# STM32F102 register map
File version: 1.2
CPU: CM3 r1p1, little endian, no MPU, no FPU, 4 interrupt priority bits
Registers are 32-bit, read-write, reset 0x0 unless marked. A register's access mark holds for its fields unless they carry their own. Offsets are from the block's base; [hi:lo] are bit positions; {n}, {i} and the like mark numbered series; 'fields as' and 'values as' point back to an identical list.

## CRC — CRC calculation unit
Base 0x40023000
0x00 DR reset 0xFFFFFFFF — Data register
  [31:0] DR — Data Register
0x04 IDR — Independent Data register
  [7:0] IDR
0x08 CR wo — Control register
  [0] RESET — Reset bit

## FLASH
Base 0x40022000
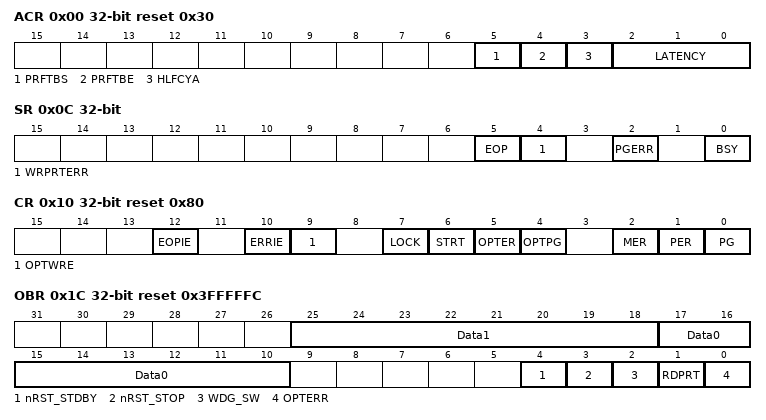
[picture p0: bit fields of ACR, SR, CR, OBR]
0x00 ACR access per field reset 0x30 — Flash access control register
  [5] PRFTBS ro — Prefetch buffer status
  [4] PRFTBE rw — Prefetch buffer enable
  [3] HLFCYA rw — Flash half cycle access enable
  [2:0] LATENCY rw
0x04 KEYR wo — Flash key register
  [31:0] KEY — FPEC key
0x08 OPTKEYR wo — Flash option key register
  [31:0] OPTKEY — Option byte key
0x0C SR access per field — Status register
  [5] EOP rw — End of operation
  [4] WRPRTERR rw — Write protection error
  [2] PGERR rw — Programming error
  [0] BSY ro — Busy
0x10 CR reset 0x80 — Control register
  [12] EOPIE — End of operation interrupt enable
  [10] ERRIE — Error interrupt enable
  [9] OPTWRE — Option bytes write enable
  [7] LOCK
  [6] STRT — Start
  [5] OPTER — Option byte erase
  [4] OPTPG — Option byte programming
  [2] MER — Mass Erase
  [1] PER — Page Erase
  [0] PG — Programming
0x14 AR wo — Flash address register
  [31:0] FAR — Flash Address
0x1C OBR ro reset 0x3FFFFFC — Option byte register
  [25:18] Data1
  [17:10] Data0
  [4] nRST_STDBY
  [3] nRST_STOP
  [2] WDG_SW
  [1] RDPRT — Read protection
  [0] OPTERR — Option byte error
0x20 WRPR ro reset 0xFFFFFFFF — Write protection register
  [31:0] WRP — Write protect

## DBG — Debug support
Base 0xE0042000
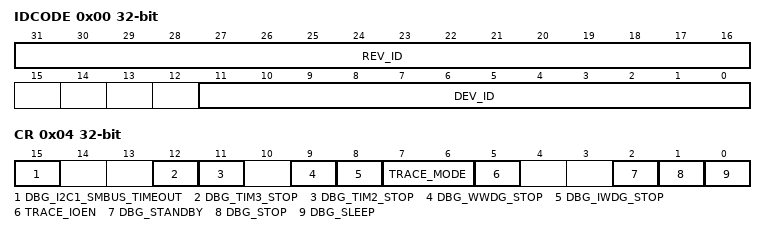
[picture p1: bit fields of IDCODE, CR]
0x00 IDCODE ro — DBGMCU_IDCODE
  [31:16] REV_ID, [11:0] DEV_ID
0x04 CR — DBGMCU_CR
  [15] DBG_I2C1_SMBUS_TIMEOUT, [12] DBG_TIM3_STOP, [11] DBG_TIM2_STOP, [9] DBG_WWDG_STOP, [8] DBG_IWDG_STOP, [7:6] TRACE_MODE, [5] TRACE_IOEN, [2] DBG_STANDBY, [1] DBG_STOP, [0] DBG_SLEEP

## BKP — Backup registers
Base 0x40006C00
0x00 DR1 — Backup data register (BKP_DR)
  [15:0] D1 — Backup data
0x04 DR2 — Backup data register (BKP_DR)
  [15:0] D2 — Backup data
0x08 DR3 — Backup data register (BKP_DR)
  [15:0] D3 — Backup data
0x0C DR4 — Backup data register (BKP_DR)
  [15:0] D4 — Backup data
0x10 DR5 — Backup data register (BKP_DR)
  [15:0] D5 — Backup data
0x14 DR6 — Backup data register (BKP_DR)
  [15:0] D6 — Backup data
0x18 DR7 — Backup data register (BKP_DR)
  [15:0] D7 — Backup data
0x1C DR8 — Backup data register (BKP_DR)
  [15:0] D8 — Backup data
0x20 DR9 — Backup data register (BKP_DR)
  [15:0] D9 — Backup data
0x24 DR10 — Backup data register (BKP_DR)
  [15:0] D10 — Backup data
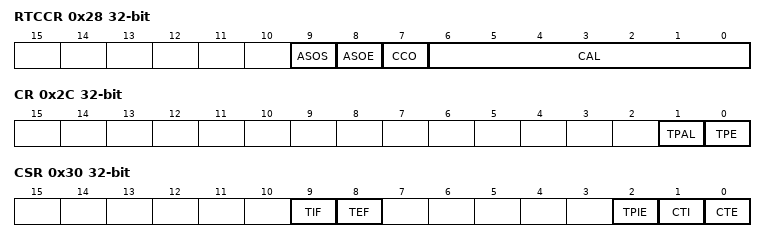
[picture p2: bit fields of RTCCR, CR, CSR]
0x28 RTCCR — RTC clock calibration register (BKP_RTCCR)
  [9] ASOS — Alarm or second output selection
  [8] ASOE — Alarm or second output enable
  [7] CCO — Calibration Clock Output
  [6:0] CAL — Calibration value
0x2C CR — Backup control register (BKP_CR)
  [1] TPAL — Tamper pin active level
  [0] TPE — Tamper pin enable
0x30 CSR access per field — BKP_CSR control/status register (BKP_CSR)
  [9] TIF ro — Tamper Interrupt Flag
  [8] TEF ro — Tamper Event Flag
  [2] TPIE rw — Tamper Pin interrupt enable
  [1] CTI wo — Clear Tamper Interrupt
  [0] CTE wo — Clear Tamper event
{0x10+4i} DR{i} (i=11..13) — Backup data register (BKP_DR)
  [15:0] DR{i} — Backup data
{0x10+4i} DR{i} (i=14..42) — Backup data register (BKP_DR)
  [15:0] D{i} — Backup data

## FSMC — Flexible static memory controller
Base 0xA0000000
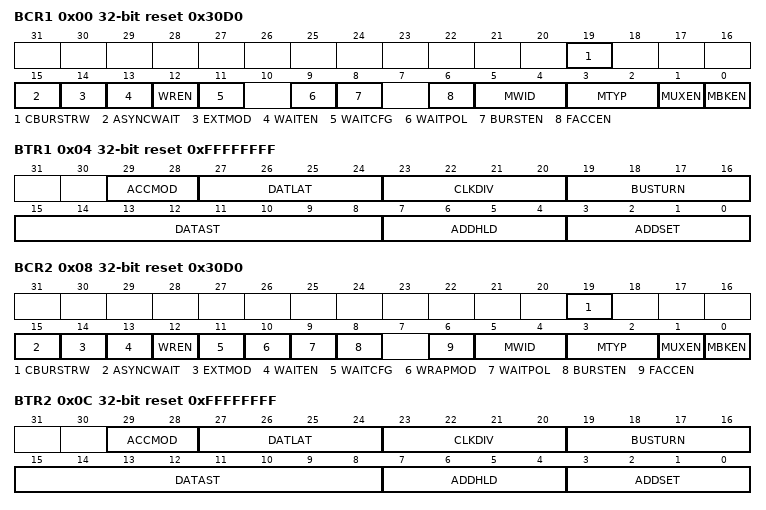
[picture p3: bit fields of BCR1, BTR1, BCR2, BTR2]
0x00 BCR1 reset 0x30D0 — SRAM/NOR-Flash chip-select control register 1
  [19] CBURSTRW, [15] ASYNCWAIT, [14] EXTMOD, [13] WAITEN, [12] WREN, [11] WAITCFG, [9] WAITPOL, [8] BURSTEN, [6] FACCEN, [5:4] MWID, [3:2] MTYP, [1] MUXEN, [0] MBKEN
0x04 BTR1 reset 0xFFFFFFFF — SRAM/NOR-Flash chip-select timing register 1
  [29:28] ACCMOD, [27:24] DATLAT, [23:20] CLKDIV, [19:16] BUSTURN, [15:8] DATAST, [7:4] ADDHLD, [3:0] ADDSET
0x08 BCR2 reset 0x30D0 — SRAM/NOR-Flash chip-select control register 2
  [19] CBURSTRW, [15] ASYNCWAIT, [14] EXTMOD, [13] WAITEN, [12] WREN, [11] WAITCFG, [10] WRAPMOD, [9] WAITPOL, [8] BURSTEN, [6] FACCEN, [5:4] MWID, [3:2] MTYP, [1] MUXEN, [0] MBKEN
0x0C BTR2 reset 0xFFFFFFFF — SRAM/NOR-Flash chip-select timing register 2
  fields as BTR1
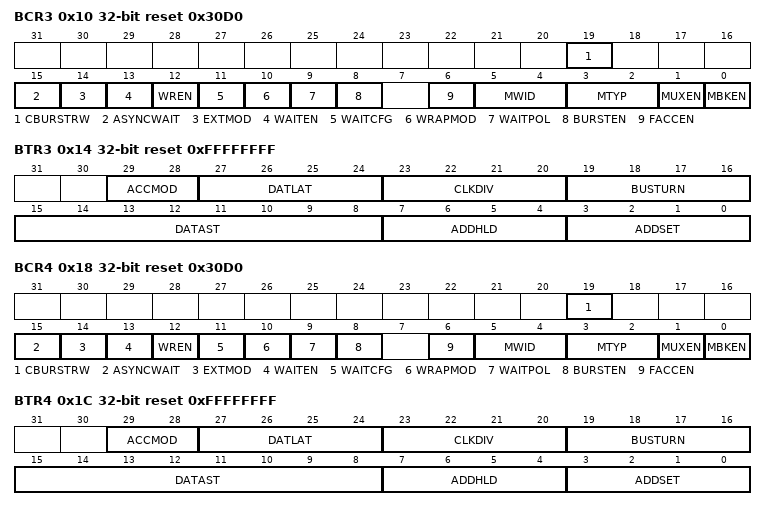
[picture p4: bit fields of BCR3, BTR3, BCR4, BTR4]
0x10 BCR3 reset 0x30D0 — SRAM/NOR-Flash chip-select control register 3
  fields as BCR2
0x14 BTR3 reset 0xFFFFFFFF — SRAM/NOR-Flash chip-select timing register 3
  fields as BTR1
0x18 BCR4 reset 0x30D0 — SRAM/NOR-Flash chip-select control register 4
  fields as BCR2
0x1C BTR4 reset 0xFFFFFFFF — SRAM/NOR-Flash chip-select timing register 4
  fields as BTR1
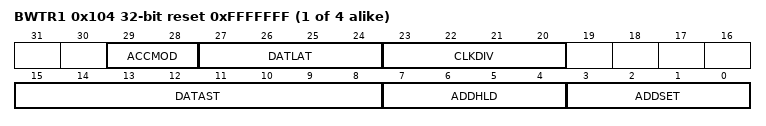
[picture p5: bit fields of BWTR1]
{0xFC+8i} BWTR{i} reset 0xFFFFFFF (i=1..4) — SRAM/NOR-Flash write timing registers {i}
  [29:28] ACCMOD, [27:24] DATLAT, [23:20] CLKDIV, [15:8] DATAST, [7:4] ADDHLD, [3:0] ADDSET
